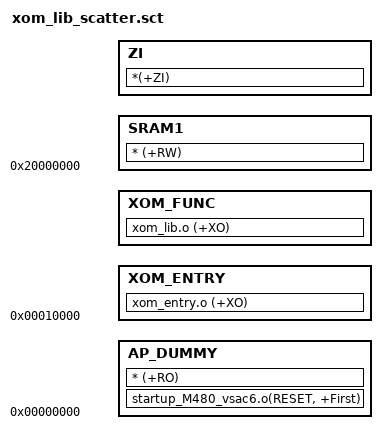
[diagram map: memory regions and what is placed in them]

AP_DUMMY 0x00000000
{
    AP_DUMMY +0
    {
        startup_M480_vsac6.o(RESET, +First)
        * (+RO)    
    }

  SRAM1 0x20000000
    {  
        * (+RW)
    }

  ZI +0
  {
    *(+ZI)
  }
}

XOM1 0x10000
{
    XOM_ENTRY +0
    {
    	xom_entry.o (+XO)
    }

    XOM_FUNC +0
    {
    	xom_lib.o (+XO)
    }
}


